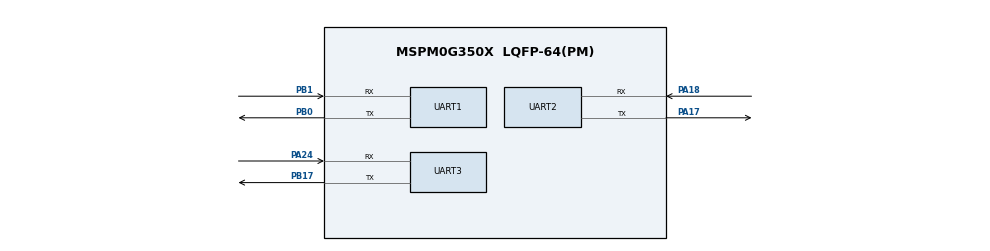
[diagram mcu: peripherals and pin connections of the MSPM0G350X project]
/**
 * @cliArgs --device "MSPM0G350X" --package "LQFP-64(PM)" --part "Default" --product "mspm0_sdk@2.01.00.03"
 * @versions {"tool":"1.20.0+3587"}
 */

/**
 * Import the modules used in this configuration.
 */
const SYSCTL = scripting.addModule("/ti/driverlib/SYSCTL");
const TIMER  = scripting.addModule("/ti/driverlib/TIMER", {}, false);
const TIMER1 = TIMER.addInstance();
const UART   = scripting.addModule("/ti/driverlib/UART", {}, false);
const UART1  = UART.addInstance();
const UART2  = UART.addInstance();
const UART3  = UART.addInstance();
const UART4  = UART.addInstance();

/**
 * Write custom configuration values to the imported modules.
 */
SYSCTL.forceDefaultClkConfig = true;

const Board = scripting.addModule("/ti/driverlib/Board", {}, false);

TIMER1.$name               = "TIMER_0";
TIMER1.timerClkPrescale    = 256;
TIMER1.timerClkDiv         = 8;
TIMER1.timerMode           = "PERIODIC";
TIMER1.interrupts          = ["REPC"];
TIMER1.enableRepeatCounter = true;
TIMER1.repeatCounter       = 2;
TIMER1.timerPeriod         = "300 ms";
TIMER1.peripheral.$assign  = "TIMA0";

UART1.$name                            = "UART_eye";
UART1.targetBaudRate                   = 115200;
UART1.enabledInterrupts                = ["RX"];
UART1.interruptPriority                = "0";
UART1.peripheral.$assign               = "UART0";
UART1.peripheral.rxPin.$assign         = "PB1";
UART1.peripheral.txPin.$assign         = "PB0";
UART1.txPinConfig.$name                = "ti_driverlib_gpio_GPIOPinGeneric0";
UART1.txPinConfig.direction            = scripting.forceWrite("OUTPUT");
UART1.txPinConfig.hideOutputInversion  = scripting.forceWrite(false);
UART1.txPinConfig.onlyInternalResistor = scripting.forceWrite(false);
UART1.txPinConfig.passedPeripheralType = scripting.forceWrite("Digital");
UART1.rxPinConfig.$name                = "ti_driverlib_gpio_GPIOPinGeneric1";
UART1.rxPinConfig.hideOutputInversion  = scripting.forceWrite(false);
UART1.rxPinConfig.onlyInternalResistor = scripting.forceWrite(false);
UART1.rxPinConfig.passedPeripheralType = scripting.forceWrite("Digital");

UART2.$name                            = "UART_arm_1";
UART2.targetBaudRate                   = 115200;
UART2.enabledInterrupts                = ["RX"];
UART2.interruptPriority                = "1";
UART2.peripheral.$assign               = "UART1";
UART2.peripheral.rxPin.$assign         = "PA18";
UART2.peripheral.txPin.$assign         = "PA17";
UART2.txPinConfig.$name                = "ti_driverlib_gpio_GPIOPinGeneric2";
UART2.txPinConfig.direction            = scripting.forceWrite("OUTPUT");
UART2.txPinConfig.hideOutputInversion  = scripting.forceWrite(false);
UART2.txPinConfig.onlyInternalResistor = scripting.forceWrite(false);
UART2.txPinConfig.passedPeripheralType = scripting.forceWrite("Digital");
UART2.rxPinConfig.$name                = "ti_driverlib_gpio_GPIOPinGeneric3";
UART2.rxPinConfig.hideOutputInversion  = scripting.forceWrite(false);
UART2.rxPinConfig.onlyInternalResistor = scripting.forceWrite(false);
UART2.rxPinConfig.passedPeripheralType = scripting.forceWrite("Digital");

UART3.$name                            = "UART_arm_2";
UART3.targetBaudRate                   = 115200;
UART3.enabledInterrupts                = ["RX"];
UART3.interruptPriority                = "1";
UART3.peripheral.$assign               = "UART2";
UART3.peripheral.rxPin.$assign         = "PA24";
UART3.peripheral.txPin.$assign         = "PB17";
UART3.txPinConfig.$name                = "ti_driverlib_gpio_GPIOPinGeneric4";
UART3.txPinConfig.direction            = scripting.forceWrite("OUTPUT");
UART3.txPinConfig.hideOutputInversion  = scripting.forceWrite(false);
UART3.txPinConfig.onlyInternalResistor = scripting.forceWrite(false);
UART3.txPinConfig.passedPeripheralType = scripting.forceWrite("Digital");
UART3.rxPinConfig.$name                = "ti_driverlib_gpio_GPIOPinGeneric5";
UART3.rxPinConfig.hideOutputInversion  = scripting.forceWrite(false);
UART3.rxPinConfig.onlyInternalResistor = scripting.forceWrite(false);
UART3.rxPinConfig.passedPeripheralType = scripting.forceWrite("Digital");

UART4.$name                            = "UART_arm_3";
UART4.targetBaudRate                   = 115200;
UART4.enabledInterrupts                = ["RX"];
UART4.interruptPriority                = "1";
UART4.peripheral.$assign               = "UART3";
UART4.txPinConfig.$name                = "ti_driverlib_gpio_GPIOPinGeneric6";
UART4.txPinConfig.direction            = scripting.forceWrite("OUTPUT");
UART4.txPinConfig.hideOutputInversion  = scripting.forceWrite(false);
UART4.txPinConfig.onlyInternalResistor = scripting.forceWrite(false);
UART4.txPinConfig.passedPeripheralType = scripting.forceWrite("Digital");
UART4.rxPinConfig.$name                = "ti_driverlib_gpio_GPIOPinGeneric7";
UART4.rxPinConfig.hideOutputInversion  = scripting.forceWrite(false);
UART4.rxPinConfig.onlyInternalResistor = scripting.forceWrite(false);
UART4.rxPinConfig.passedPeripheralType = scripting.forceWrite("Digital");

/**
 * Pinmux solution for unlocked pins/peripherals. This ensures that minor changes to the automatic solver in a future
 * version of the tool will not impact the pinmux you originally saw.  These lines can be completely deleted in order to
 * re-solve from scratch.
 */
SYSCTL.peripheral.$suggestSolution         = "SYSCTL";
Board.peripheral.$suggestSolution          = "DEBUGSS";
Board.peripheral.swclkPin.$suggestSolution = "PA20";
Board.peripheral.swdioPin.$suggestSolution = "PA19";
UART4.peripheral.rxPin.$suggestSolution    = "PA13";
UART4.peripheral.txPin.$suggestSolution    = "PA14";
